# STM32WB5Mxx register map
File version: 1.0
Registers are 32-bit, read-write, reset 0x0 unless marked. A register's access mark holds for its fields unless they carry their own. Offsets are from the block's base; [hi:lo] are bit positions; {n}, {i} and the like mark numbered series; 'fields as' and 'values as' point back to an identical list.

## COMP12_COMMON
Base 0x40010204
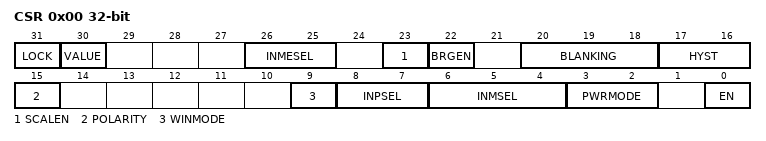
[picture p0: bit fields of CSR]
0x00 CSR — COMP control and status register, used for bits common to several COMP instances
  [31] LOCK — Comparator lock
  [30] VALUE — Comparator output level
  [26:25] INMESEL — Comparator input minus extended selection
  [23] SCALEN — Comparator scaler bridge enable
  [22] BRGEN — Comparator voltage scaler enable
  [20:18] BLANKING — Comparator blanking source
    0=NONE (Comparator output without blanking); 1=TIM1_OC5 (Comparator output blanking source TIM1 OC5 (common to all COMP instances: COMP1, COMP2)); 2=TIM2_OC3 (Comparator output blanking source TIM2 OC3 (common to all COMP instances: COMP1, COMP2))
  [17:16] HYST — Comparator hysteresis
    0=NONE (No hysteresis); 1=LOW (Hysteresis level low); 2=MEDIUM (Hysteresis level medium); 3=HIGH (Hysteresis level high)
  [15] POLARITY — Comparator output polarity
    0=NONINVERTED (COMP output polarity is not inverted: comparator output is high when the plus (non-inverting) input is at a higher voltage than the minus (inverting) input); 1=INVERTED (COMP output polarity is inverted: comparator output is low when the plus (non-inverting) input is at a lower voltage than the minus (inverting) input)
  [9] WINMODE — Pair of comparators window mode. Bit intended to be used with COMP common instance (COMP_Common_TypeDef)
    0=DISABLE (Window mode disable: Comparators 1 and 2 are independent); 1=COMP1_INPUT_PLUS_COMMON (Window mode enable: Comparators instances pair COMP1 and COMP2 have their input plus connected together. The common input is COMP1 input plus (COMP2 input plus is no more accessible).)
  [8:7] INPSEL — Comparator input plus selection
    0=IO1 (Comparator input plus connected to IO1 (pin PC5 for COMP1 (except device STM32WB35xx), pin PB4 for COMP2). Note: On STM32WB series, parameter not available on devices: STM32WB10xx, STM32WB15xx, STM32WB1Mxx.); 1=IO2 (Comparator input plus connected to IO2 (pin PB2 for COMP1, pin PB6 for COMP2)); 2=IO3 (Comparator input plus connected to IO3 (pin PA1 for COMP1, pin PA3 for COMP2))
  [6:4] INMSEL — Comparator input minus selection
  [3:2] PWRMODE — Comparator power mode
    0=HIGHSPEED (COMP power mode to high speed); 1=MEDIUMSPEED (COMP power mode to medium speed); 3=ULTRALOWPOWER (COMP power mode to ultra-low power)
  [0] EN — Comparator enable

## DMA1
Base 0x40020000
Same registers: DMA2 0x40020400
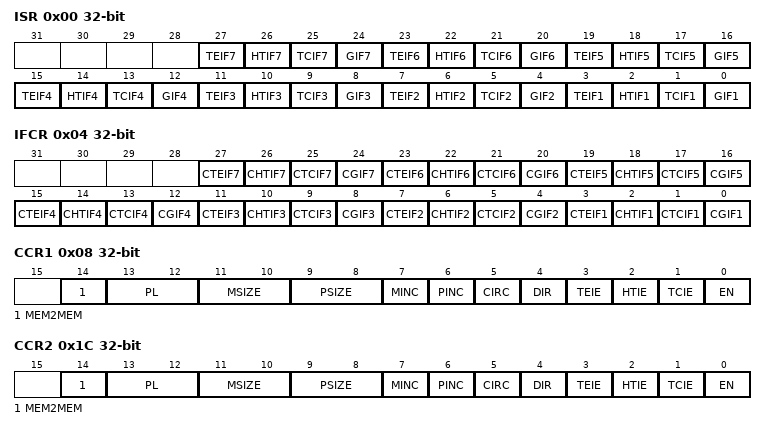
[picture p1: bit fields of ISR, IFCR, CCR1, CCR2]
0x00 ISR — DMA interrupt status register
  [4n-1] TEIF{n} (n=1..7) — Channel {n} Transfer Error flag
  [4n-2] HTIF{n} (n=1..7) — Channel {n} Half Transfer flag
  [4n-3] TCIF{n} (n=1..7) — Channel {n} Transfer Complete flag
  [4n-4] GIF{n} (n=1..7) — Channel {n} Global interrupt flag
0x04 IFCR — DMA interrupt flag clear register
  [4n-1] CTEIF{n} (n=1..7) — Channel {n} Transfer Error clear
  [4n-2] CHTIF{n} (n=1..7) — Channel {n} Half Transfer clear
  [4n-3] CTCIF{n} (n=1..7) — Channel {n} Transfer Complete clear
  [4n-4] CGIF{n} (n=1..7) — Channel {n} Global interrupt clear
0x08 CCR1 — DMA channel x configuration register 0x00
  [14] MEM2MEM — Memory to memory mode
  [13:12] PL — PL[1:0] bits(Channel Priority level)
  [11:10] MSIZE — MSIZE[1:0] bits (Memory size)
  [9:8] PSIZE — PSIZE[1:0] bits (Peripheral size)
  [7] MINC — Memory increment mode
  [6] PINC — Peripheral increment mode
  [5] CIRC — Circular mode
  [4] DIR — Data transfer direction
  [3] TEIE — Transfer error interrupt enable
  [2] HTIE — Half Transfer interrupt enable
  [1] TCIE — Transfer complete interrupt enable
  [0] EN — Channel enable
0x0C CNDTR1 — DMA channel x number of data register 0x04
  [15:0] NDT — Number of data to Transfer
0x10 CPAR1 — DMA channel x peripheral address register 0x08
  [31:0] PA — Peripheral Address
{0x0+0x14*i} CMAR{i} (i=1..7) — DMA channel x memory address register 0x0C
  [31:0] MA — Memory Address
0x1C CCR2 — DMA channel x configuration register 0x00
  fields as CCR1
0x20 CNDTR2 — DMA channel x number of data register 0x04
  [15:0] NDT — Number of data to Transfer
0x24 CPAR2 — DMA channel x peripheral address register 0x08
  [31:0] PA — Peripheral Address
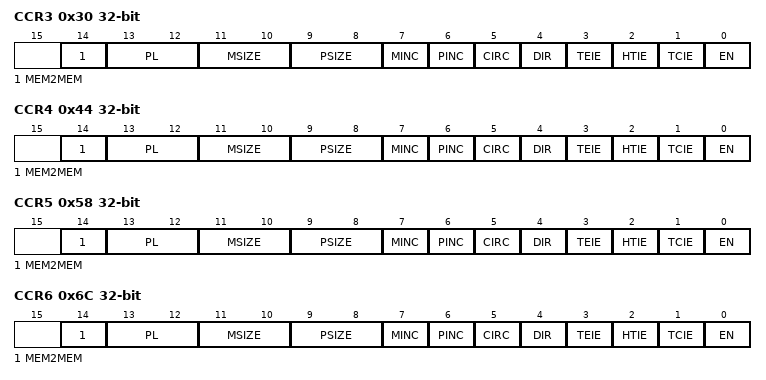
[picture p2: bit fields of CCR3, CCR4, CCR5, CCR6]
0x30 CCR3 — DMA channel x configuration register 0x00
  fields as CCR1
0x34 CNDTR3 — DMA channel x number of data register 0x04
  [15:0] NDT — Number of data to Transfer
0x38 CPAR3 — DMA channel x peripheral address register 0x08
  [31:0] PA — Peripheral Address
0x44 CCR4 — DMA channel x configuration register 0x00
  fields as CCR1
0x48 CNDTR4 — DMA channel x number of data register 0x04
  [15:0] NDT — Number of data to Transfer
0x4C CPAR4 — DMA channel x peripheral address register 0x08
  [31:0] PA — Peripheral Address
0x58 CCR5 — DMA channel x configuration register 0x00
  fields as CCR1
0x5C CNDTR5 — DMA channel x number of data register 0x04
  [15:0] NDT — Number of data to Transfer
0x60 CPAR5 — DMA channel x peripheral address register 0x08
  [31:0] PA — Peripheral Address
0x6C CCR6 — DMA channel x configuration register 0x00
  fields as CCR1
0x70 CNDTR6 — DMA channel x number of data register 0x04
  [15:0] NDT — Number of data to Transfer
0x74 CPAR6 — DMA channel x peripheral address register 0x08
  [31:0] PA — Peripheral Address
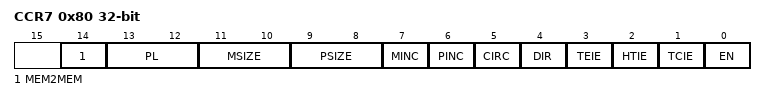
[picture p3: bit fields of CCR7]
0x80 CCR7 — DMA channel x configuration register 0x00
  fields as CCR1
0x84 CNDTR7 — DMA channel x number of data register 0x04
  [15:0] NDT — Number of data to Transfer
0x88 CPAR7 — DMA channel x peripheral address register 0x08
  [31:0] PA — Peripheral Address
